# STM32H743 register map
File version: 2.4
CPU: CM7 r0p1, little endian, MPU, FPU, 4 interrupt priority bits
Registers are 32-bit, read-write, reset 0x0 unless marked. A register's access mark holds for its fields unless they carry their own. Offsets are from the block's base; [hi:lo] are bit positions; {n}, {i} and the like mark numbered series.

## EXTI — 外部中断/事件控制器
Base 0x58000000
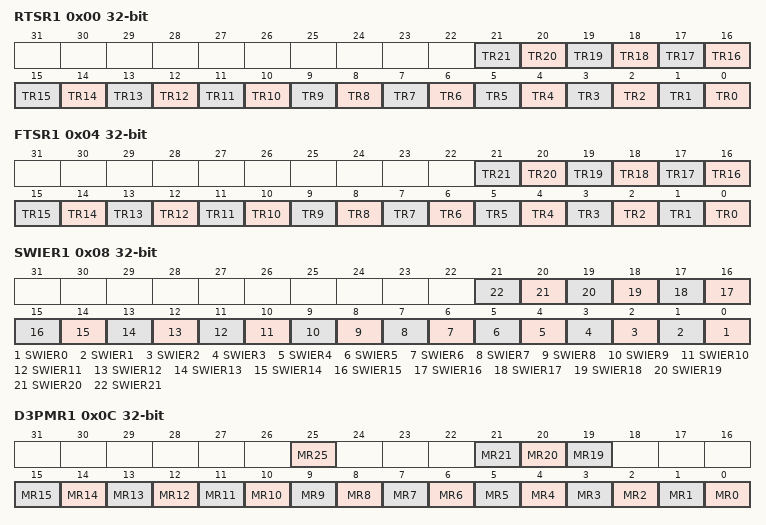
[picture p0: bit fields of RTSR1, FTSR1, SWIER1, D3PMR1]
0x00 RTSR1 — EXTI 上升沿触发选择寄存器
  [n] TR{n} (n=0..21) — 可配置事件输入的上升沿触发事件配置位
0x04 FTSR1 — EXTI 下降沿触发选择寄存器
  [n] TR{n} (n=0..21) — 可配置事件输入的上升沿触发事件配置位
0x08 SWIER1 — EXTI 软件中断事件寄存器
  [n] SWIER{n} (n=0..21) — 可配置事件输入的上升沿触发事件配置位
0x0C D3PMR1 — EXTI D3 挂起屏蔽寄存器
  [25] MR25 — 可配置事件输入的上升沿触发事件配置位
  [21] MR21 — 可配置事件输入的上升沿触发事件配置位
  [20] MR20 — 可配置事件输入的上升沿触发事件配置位
  [19] MR19 — 可配置事件输入的上升沿触发事件配置位
  [n] MR{n} (n=0..15) — 可配置事件输入的上升沿触发事件配置位
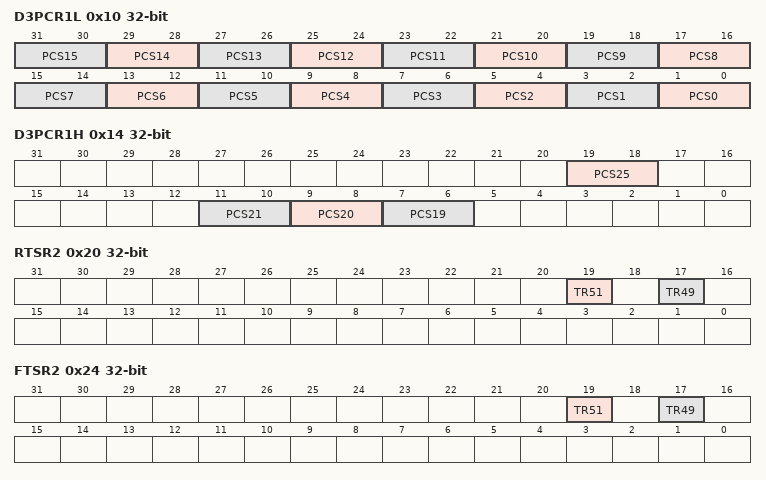
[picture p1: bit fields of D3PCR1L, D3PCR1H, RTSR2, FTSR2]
0x10 D3PCR1L — EXTI D3 挂起清除选择寄存器（低位）
  [2n+1:2n] PCS{n} (n=0..15) — 事件输入 x = truncate(n/2) 的 D3 挂起请求清除输入信号选择
0x14 D3PCR1H — EXTI D3 挂起清除选择寄存器（高位）
  [19:18] PCS25 — 事件输入 x = truncate((n+32)/2) 的 D3 挂起请求清除输入信号选择
  [11:10] PCS21 — 事件输入 x = truncate((n+32)/2) 的 D3 挂起请求清除输入信号选择
  [9:8] PCS20 — 事件输入 x = truncate((n+32)/2) 的 D3 挂起请求清除输入信号选择
  [7:6] PCS19 — 事件输入 x = truncate((n+32)/2) 的 D3 挂起请求清除输入信号选择
0x20 RTSR2 — EXTI 上升沿触发选择寄存器
  [19] TR51 — 可配置事件输入 x+32 的上升沿触发事件配置位
  [17] TR49 — 可配置事件输入 x+32 的上升沿触发事件配置位
0x24 FTSR2 — EXTI 下降沿触发选择寄存器
  [19] TR51 — 可配置事件输入 x+32 的下降沿触发事件配置位
  [17] TR49 — 可配置事件输入 x+32 的下降沿触发事件配置位
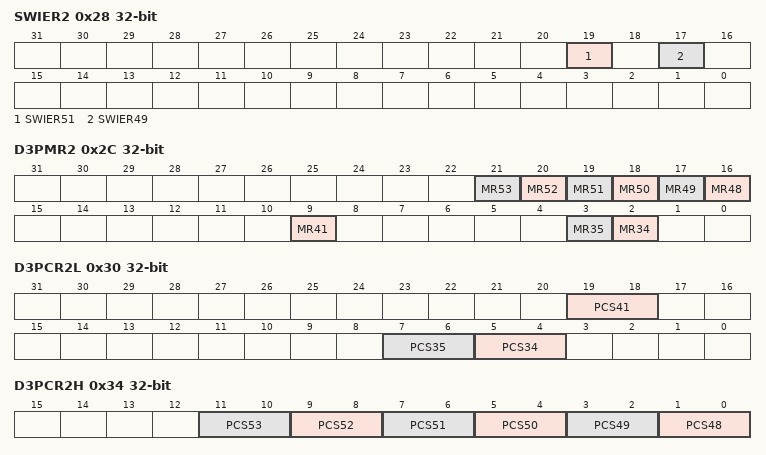
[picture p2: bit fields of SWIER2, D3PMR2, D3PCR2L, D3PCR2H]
0x28 SWIER2 — EXTI 软件中断事件寄存器
  [19] SWIER51 — 线 x+32 的软件中断
  [17] SWIER49 — 线 x+32 的软件中断
0x2C D3PMR2 — EXTI D3 挂起屏蔽寄存器
  [n-32] MR{n} (n=48..53) — 事件输入 x+32 的 D3 挂起屏蔽
  [9] MR41 — 事件输入 x+32 的 D3 挂起屏蔽
  [3] MR35 — 事件输入 x+32 的 D3 挂起屏蔽
  [2] MR34 — 事件输入 x+32 的 D3 挂起屏蔽
0x30 D3PCR2L — EXTI D3 挂起清除选择寄存器（低位）
  [19:18] PCS41 — 事件输入 x = truncate((n+64)/2) 的 D3 挂起请求清除输入信号选择
  [7:6] PCS35 — 事件输入 x = truncate((n+64)/2) 的 D3 挂起请求清除输入信号选择
  [5:4] PCS34 — 事件输入 x = truncate((n+64)/2) 的 D3 挂起请求清除输入信号选择
0x34 D3PCR2H — EXTI D3 挂起清除选择寄存器（高位）
  [2n-95:2n-96] PCS{n} (n=48..53) — 事件输入 x = truncate((n+96)/2) 的挂起请求清除输入信号选择
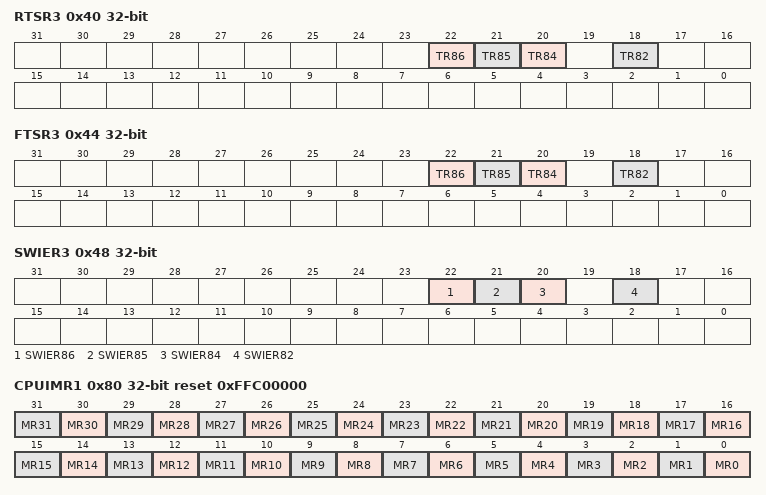
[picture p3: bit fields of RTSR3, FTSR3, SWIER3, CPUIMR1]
0x40 RTSR3 — EXTI 上升沿触发选择寄存器
  [22] TR86 — 可配置事件输入 x+64 的上升沿触发事件配置位
  [21] TR85 — 可配置事件输入 x+64 的上升沿触发事件配置位
  [20] TR84 — 可配置事件输入 x+64 的上升沿触发事件配置位
  [18] TR82 — 可配置事件输入 x+64 的上升沿触发事件配置位
0x44 FTSR3 — EXTI 下降沿触发选择寄存器
  [22] TR86 — 可配置事件输入 x+64 的下降沿触发事件配置位
  [21] TR85 — 可配置事件输入 x+64 的下降沿触发事件配置位
  [20] TR84 — 可配置事件输入 x+64 的下降沿触发事件配置位
  [18] TR82 — 可配置事件输入 x+64 的下降沿触发事件配置位
0x48 SWIER3 — EXTI 软件中断事件寄存器
  [22] SWIER86 — 线 x+64 的软件中断
  [21] SWIER85 — 线 x+64 的软件中断
  [20] SWIER84 — 线 x+64 的软件中断
  [18] SWIER82 — 线 x+64 的软件中断
0x4C D3PMR3 — EXTI D3 挂起屏蔽寄存器
  [24] MR88 — 事件输入 x+64 的 D3 挂起屏蔽
0x54 D3PCR3H — EXTI D3 挂起清除选择寄存器（高位）
  [19:18] PCS88 — 事件输入 x = truncate((N+160)/2) 的 D3 挂起请求清除输入信号选择
0x80 CPUIMR1 reset 0xFFC00000 — EXTI 中断屏蔽寄存器
  [n] MR{n} (n=0..31) — 可配置事件输入的上升沿触发事件配置位
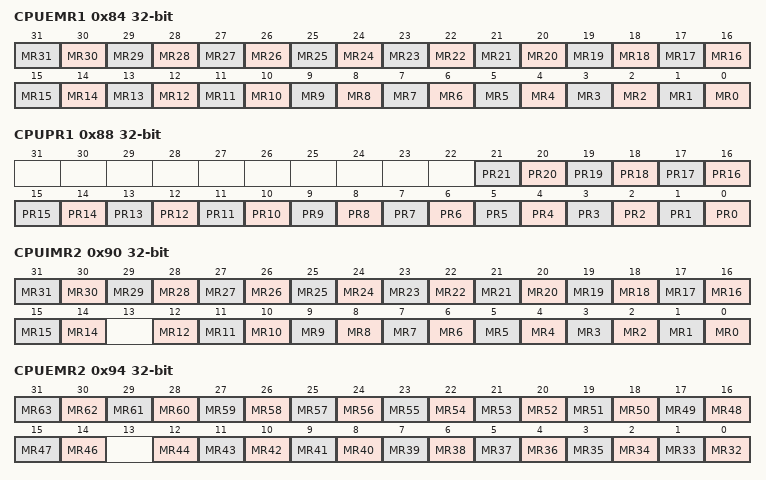
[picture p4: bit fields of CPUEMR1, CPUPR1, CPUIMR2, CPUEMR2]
0x84 CPUEMR1 — EXTI 事件屏蔽寄存器
  [n] MR{n} (n=0..31) — 事件输入 x 的 CPU 事件屏蔽
0x88 CPUPR1 — EXTI 挂起寄存器
  [n] PR{n} (n=0..21) — 事件输入 x 的 CPU 事件屏蔽
0x90 CPUIMR2 — EXTI 中断屏蔽寄存器
  [n] MR{n} (n=14..31) — 直接事件输入 x+32 的 CPU 中断屏蔽
  [n] MR{n} (n=0..12) — 直接事件输入 x+32 的 CPU 中断屏蔽
0x94 CPUEMR2 — EXTI 事件屏蔽寄存器
  [n-32] MR{n} (n=46..63) — 直接事件输入 x+32 的 CPU 中断屏蔽
  [n-32] MR{n} (n=32..44) — 直接事件输入 x+32 的 CPU 中断屏蔽
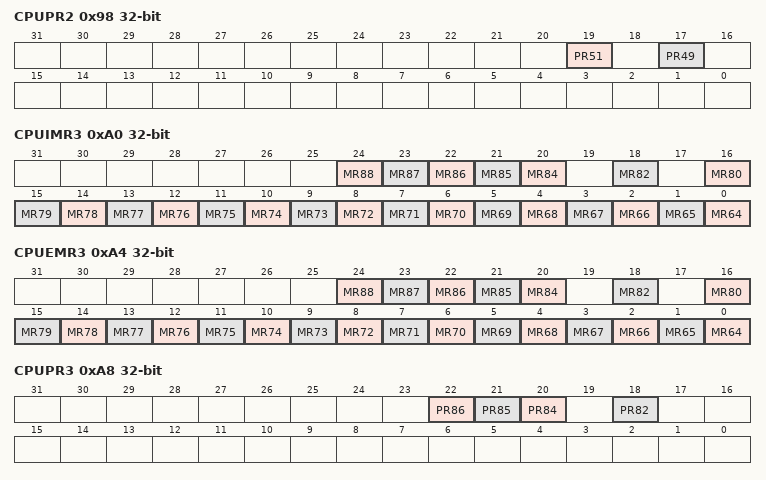
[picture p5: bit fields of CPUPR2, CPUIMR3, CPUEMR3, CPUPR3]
0x98 CPUPR2 ro — EXTI 挂起寄存器
  [19] PR51 — 可配置事件输入 x+32 的挂起位
  [17] PR49 — 可配置事件输入 x+32 的挂起位
0xA0 CPUIMR3 ro — EXTI 中断屏蔽寄存器
  [n-64] MR{n} (n=84..88) — 直接事件输入 x+64 的 CPU 中断屏蔽
  [18] MR82 — 直接事件输入 x+64 的 CPU 中断屏蔽
  [n-64] MR{n} (n=64..80) — 直接事件输入 x+64 的 CPU 中断屏蔽
0xA4 CPUEMR3 ro — EXTI 事件屏蔽寄存器
  [n-64] MR{n} (n=84..88) — 事件输入 x+64 的 CPU 事件屏蔽
  [18] MR82 — 事件输入 x+64 的 CPU 事件屏蔽
  [n-64] MR{n} (n=64..80) — 事件输入 x+64 的 CPU 事件屏蔽
0xA8 CPUPR3 ro — EXTI 挂起寄存器
  [22] PR86 — 可配置事件输入 x+64 的挂起位
  [21] PR85 — 可配置事件输入 x+64 的挂起位
  [20] PR84 — 可配置事件输入 x+64 的挂起位
  [18] PR82 — 可配置事件输入 x+64 的挂起位

## RAMECC1 — ECC 控制器关联到各 RAM 区域
Base 0x52009000
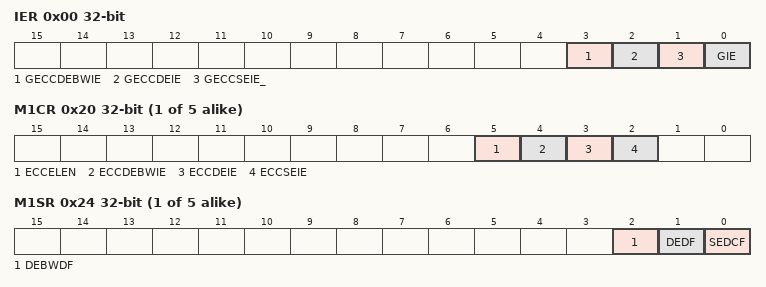
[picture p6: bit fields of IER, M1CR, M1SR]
0x00 IER — RAMECC 中断使能寄存器
  [3] GECCDEBWIE — 全局 ECC 字节写入双错误中断使能
  [2] GECCDEIE — 全局 ECC 双错误中断使能
  [1] GECCSEIE_ — 全局 ECC 单错误中断使能
  [0] GIE — 全局中断使能
{0x0+0x20*i} M{i}CR (i=1..5) — RAMECC 监视器 {i} 配置寄存器
  [5] ECCELEN — ECC 错误锁存使能
  [4] ECCDEBWIE — ECC 字节写入双错误中断使能
  [3] ECCDEIE — ECC 双错误中断使能
  [2] ECCSEIE — ECC 单错误中断使能
{0x4+0x20*i} M{i}SR (i=1..5) — RAMECC 监视器 {i} 状态寄存器
  [2] DEBWDF — ECC 字节写入双错误检测标志
  [1] DEDF — ECC 双错误检测标志
  [0] SEDCF — ECC 单错误检测与纠正标志
{0x8+0x20*i} M{i}FAR ro (i=1..4) — RAMECC 监视器 {i} 故障地址寄存器
  [31:0] FADD — ECC 错误故障地址
{0xC+0x20*i} M{i}FDRL ro (i=1..5) — RAMECC 监视器 {i} 故障数据低位寄存器
  [31:0] FDATAL — 故障数据低位
0x30 M1FDRH ro — RAMECC 监视器 1 故障数据高位寄存器
  [31:0] FDATAH — 故障数据高位（64 位存储器）
0x34 M1FECR — RAMECC 监视器 1 故障 ECC 错误码寄存器
  [31:0] FEC — 故障错误码
0x50 M2FDRH — RAMECC 监视器 2 故障数据高位寄存器
  [31:0] FDATAH — 故障数据高位（64 位存储器）
0x58 M2FECR — RAMECC 监视器 2 故障 ECC 错误码寄存器
  [31:0] FEC — 故障错误码
0x70 M3FDRH ro — RAMECC 监视器 3 故障数据高位寄存器
  [31:0] FDATAH — 故障数据高位（64 位存储器）
0x7C M3FECR ro — RAMECC 监视器 3 故障 ECC 错误码寄存器
  [31:0] FEC — 故障错误码
0x90 M4FDRH ro — RAMECC 监视器 4 故障数据高位寄存器
  [31:0] FDATAH — 故障数据高位（64 位存储器）
0x90 M4FECR ro (alternate view of M4FDRH) — RAMECC 监视器 4 故障 ECC 错误码寄存器
  [31:0] FEC — 故障错误码
0xA8 M5FAR — RAMECC 监视器 5 故障地址寄存器
  [31:0] FADD — ECC 错误故障地址
0xB0 M5FDRH ro — RAMECC 监视器 5 故障数据高位寄存器
  [31:0] FEC — 故障错误码
0xB4 M5FECR ro — RAMECC 监视器 5 故障 ECC 错误码寄存器
  [31:0] FEC — 故障错误码
